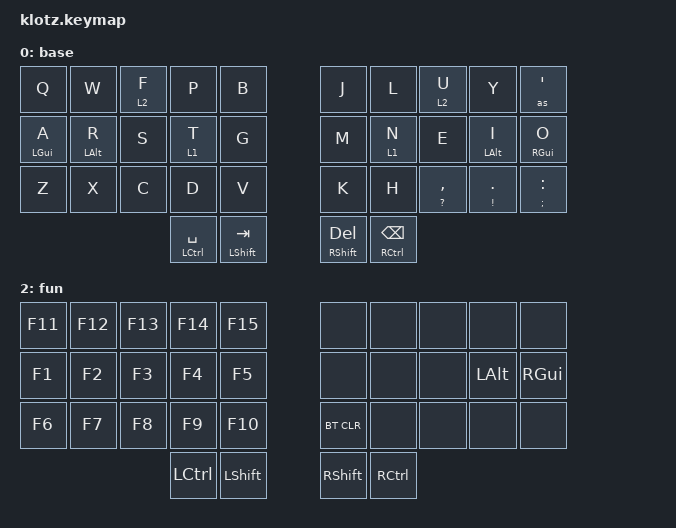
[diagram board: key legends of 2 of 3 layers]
//                                      █         ██        ▄▀▀▀▀▀▀▀▀▀▀█▀▀▀▀▀▀▀▀█▀▀▀▀▀▀▀▀▀▀█
//                                      █        █ █      ▄▀            ▀▄      █         █
//                                      █       █  █    ▄▀                ▀▄    █        █
//                                      █      █   █   █                    █   █       █
//                                      █     █    █   █                    █   █      █
//                                      █    █     █   █                    █   █  ▀▀▀█▀▀▀▀
//                                      █   █ █    █   █                    █   █    █
//                                      █  █   █   █   █                    █   █   █
//                                      █ █     █  █    ▀▄                ▄▀    █  █
//                                      ██       █ █      ▀▄            ▄▀      █ █
//                                      █         ██▄▄▄▄▄▄▄▄█▄▄▄▄▄▄▄▄▄▄▀        ██▄▄▄▄▄▄▄▄▄▄
//
// ▄▄▄▄▄▄▄▄▄▄▄▄▄▄▄▄▄▄▄▄▄▄▄▄▄▄▄▄▄▄▄▄▄▄▄▄▄▄▄▄▄▄▄▄▄▄▄▄▄▄▄▄▄▄▄▄▄▄▄▄▄▄▄▄▄▄▄▄▄▄▄▄▄▄▄▄▄▄▄▄▄▄▄▄▄▄▄▄▄▄▄▄▄▄▄▄▄▄▄▄▄▄▄▄▄▄▄▄▄▄▄▄▄▄▄▄▄▄▄▄▄▄▄▄▄


#include <behaviors.dtsi>
#include <dt-bindings/zmk/keys.h>
#include <dt-bindings/zmk/bt.h>
#include <dt-bindings/zmk/pointing.h>

&lt {
    quick-tap-ms = <175>;
    flavor = "balanced";
    require-prior-idle-ms = <150>;
};

&mt {
    quick-tap-ms = <175>;
    flavor = "balanced";
    require-prior-idle-ms = <150>;
};

/ {
    behaviors {
        hml: home_row_mod_left {
            display-name = "Home Row Mod (Left)";
            compatible = "zmk,behavior-hold-tap";
            #binding-cells = <2>;
            bindings = <&kp>, <&kp>;

            tapping-term-ms = <280>;
            quick-tap-ms = <175>;
            require-prior-idle-ms = <150>;
            flavor = "balanced";
            hold-trigger-on-release;
            hold-trigger-key-positions = <5 7 6 8 9 19 30 31 18 17 16 15 26 28 27 29 37 36 35 34 33 32>;
        };

        hmr: home_row_mod_right {
            display-name = "Home Row Mod (Right)";
            compatible = "zmk,behavior-hold-tap";
            bindings = <&kp>, <&kp>;

            #binding-cells = <2>;
            tapping-term-ms = <280>;
            quick-tap-ms = <175>;
            require-prior-idle-ms = <150>;
            flavor = "balanced";
            hold-trigger-on-release;
            hold-trigger-key-positions = <0 1 2 3 4 14 13 12 11 10 20 21 22 23 24 25 32 33 34 35 36 37>;
        };

        hll: home_row_layer_tap_left {
            compatible = "zmk,behavior-hold-tap";
            bindings = <&mo>, <&kp>;

            #binding-cells = <2>;
            tapping-term-ms = <280>;
            quick-tap-ms = <175>;
            require-prior-idle-ms = <150>;
            flavor = "balanced";
            hold-trigger-on-release;
            hold-trigger-key-positions = <5 6 7 9 31 19 29 18 17 8 16 15 26 27 28 30 37 36 35 34 33 32>;
        };

        hlr: home_row_layer_tap_right {
            compatible = "zmk,behavior-hold-tap";
            bindings = <&mo>, <&kp>;

            #binding-cells = <2>;
            tapping-term-ms = <280>;
            quick-tap-ms = <175>;
            require-prior-idle-ms = <150>;
            flavor = "balanced";
            hold-trigger-on-release;
            hold-trigger-key-positions = <4 3 2 1 0 20 10 11 21 12 13 14 23 22 24 25 32 33 34 35 36 37>;
        };

        as_ht: autoshift_hold_tap {
            compatible = "zmk,behavior-hold-tap";
			display-name = "Autoshift Hold-Tap";
            bindings = <&sh>, <&kp>;

            #binding-cells = <2>;
            tapping-term-ms = <135>;
            flavor = "tap-preferred";
        };

        scroll_right_left {
            compatible = "zmk,behavior-sense-rotate";
            display-name = "Scroll Right-Left";
            #sensor-binding-cells = <0>;
            bindings = <&msc SCRL_RIGHT>, <&msc SCRL_LEFT>;
            tap-ms = <250>;
        };

        scroll_up_down {
            compatible = "zmk,behavior-sense-rotate";
            display-name = "Scroll Up-Down";
            #sensor-binding-cells = <0>;
            bindings = <&msc SCRL_UP>, <&msc SCRL_DOWN>;
            tap-ms = <250>;
        };

        bt_prev_next {
            compatible = "zmk,behavior-sense-rotate";
            display-name = "Bluetooth Prev-Next";
            #sensor-binding-cells = <0>;
            bindings = <&bt BT_PREV>, <&bt BT_NEXT>;
        }
    };

    macros {
        sh: shifted {
            compatible = "zmk,behavior-macro-one-param";
            display-name = "shifted";
            bindings = <&macro_press &kp LSHFT>,
                        <&macro_param_1to1 &macro_tap &kp MACRO_PLACEHOLDER>,
                        <&macro_release &kp LSHFT>;

            #binding-cells = <1>;
        };

        as: autoshift {
            compatible = "zmk,behavior-macro-one-param";
            display-name = "Autoshift";
            bindings = <&macro_press>, <&macro_param_1to1>, <&macro_param_1to2>,
                        <&as_ht MACRO_PLACEHOLDER MACRO_PLACEHOLDER>,
                        <&macro_pause_for_release>, <&macro_release>,
                        <&macro_param_1to1>, <&macro_param_1to2>,
                        <&as_ht MACRO_PLACEHOLDER MACRO_PLACEHOLDER>;

            #binding-cells = <1>;
        };
    };

    combos {
        compatible = "zmk,combos";

        bslh {
            bindings = <&kp BSLH>;
            key-positions = <0 10>;
            layers = <0>;
        };

        lbrc {
            bindings = <&kp LBRC>;
            key-positions = <1 11>;
            layers = <0>;
        };

        lbkt {
            bindings = <&kp LBKT>;
            key-positions = <2 12>;
            layers = <0>;
        };

        lpar {
            bindings = <&kp LPAR>;
            key-positions = <3 13>;
            layers = <0>;
        };

        lt {
            bindings = <&kp LT>;
            key-positions = <4 14>;
            layers = <0>;
        };

        gt {
            bindings = <&kp GT>;
            key-positions = <5 15>;
            layers = <0>;
        };

        rpar {
            bindings = <&kp RPAR>;
            key-positions = <6 16>;
            layers = <0>;
        };

        rbkt {
            bindings = <&kp RBKT>;
            key-positions = <7 17>;
            layers = <0>;
        };

        rbrc {
            bindings = <&kp RBRC>;
            key-positions = <8 18>;
            layers = <0>;
        };

        fslh {
            bindings = <&kp FSLH>;
            key-positions = <9 19>;
            layers = <0>;
        }

        launcher_l {
            bindings = <&kp LG(SPACE)>;
            key-positions = <11 13>;
            layers = <0>;
        };

        launcher_r {
            bindings = <&kp RG(SPACE)>;
            key-positions = <16 18>;
            layers = <0>;
        };

        esc {
            bindings = <&kp ESC>;
            key-positions = <11 12 13>;
            layers = <0>;
        }

        return {
            bindings = <&kp RET>;
            key-positions = <16 17 18>;
            layers = <0>;
        }
    };

    keymap {
        compatible = "zmk,keymap";

        base {
            display-name = "base";
            bindings = <
&kp Q         &kp W         &hll 2 F   &kp P           &kp B              &kp J           &kp L            &hlr 2 U             &kp Y             &as SQT
&hml LGUI A   &hml LALT R   &kp S      &hll 1 T        &kp G              &kp M           &hlr 1 N         &kp E                &hmr LALT I       &hmr RGUI O
&kp Z         &kp X         &kp C      &kp D           &kp V              &kp K           &kp H            &as_ht QMARK COMMA   &as_ht EXCL DOT   &as_ht SEMI COLON
                                       &mt LCTRL SPC   &mt LSHFT TAB      &mt RSHFT DEL   &mt RCTRL BSPC
            >;
            sensor-bindings = <&scroll_right_left &scroll_up_down>;
        };

        navigation {
            display-name= "nav";
            bindings = <
&kp BSLH      &kp FSLH   &kp PLUS   &kp EQUAL         &none                &kp HOME          &kp PG_DN         &kp PG_UP   &kp END     &kp INS
&as PIPE N1   &as N2     &as N3     &as N4            &as N5               &kp LEFT          &kp DOWN          &kp UP      &kp RIGHT   &kp RGUI
&as N6        &as N7     &as N8     &as_ht GRAVE N9   &as_ht TILDE N0      &kp PSCRN         &kp LC(PSCRN)     &none       &kp LALT    &none
                                    &mt LCTRL UNDER   &mt LSHFT MINUS      &mt RSHFT MINUS   &mt RCTRL UNDER
            >;
            sensor-bindings = <&inc_dec_kp RIGHT LEFT &inc_dec_kp UP DOWN>;
        };

        function {
            display-name = "fun";
            bindings = <
&kp F11   &kp F12   &kp F13   &kp F14     &kp F15        &none       &none       &none   &none      &none
&kp F1    &kp F2    &kp F3    &kp F4      &kp F5         &none       &none       &none   &kp LALT   &kp RGUI
&kp F6    &kp F7    &kp F8    &kp F9      &kp F10        &bt BT_CLR  &none       &none   &none      &none
                              &kp LCTRL   &kp LSHFT      &kp RSHFT   &kp RCTRL
            >;
            sensor-bindings = <&bt_prev_next &bt_prev_next>;
        };
    };
};
